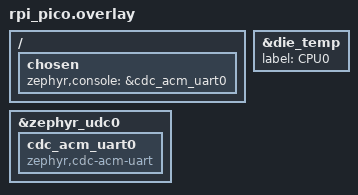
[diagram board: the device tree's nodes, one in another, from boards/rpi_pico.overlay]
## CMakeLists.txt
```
# SPDX-License-Identifier: Apache-2.0

cmake_minimum_required(VERSION 3.20.0)

find_package(Zephyr REQUIRED HINTS $ENV{ZEPHYR_BASE})
project(rpi_cpu_temp)

target_sources(app PRIVATE src/main.c)
```

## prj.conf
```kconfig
CONFIG_SENSOR=y
CONFIG_ADC=y
CONFIG_PRINTK=y
CONFIG_CBPRINTF_FP_SUPPORT=y

# Use UART over USB as a console
CONFIG_SERIAL=y
CONFIG_CONSOLE=y
CONFIG_UART_CONSOLE=y
CONFIG_UART_LINE_CTRL=y

# Use USB CDC ACM (whathever it means)
CONFIG_USB_DEVICE_STACK_NEXT=y
CONFIG_CDC_ACM_SERIAL_INITIALIZE_AT_BOOT=y
CONFIG_CDC_ACM_SERIAL_PID=0x0004
CONFIG_CDC_ACM_SERIAL_PRODUCT_STRING="Zephyr core temp"
```

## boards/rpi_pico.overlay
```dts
/*
 * SPDX-License-Identifier: Apache-2.0
 *
 * Copyright (c) 2023 TOKITA Hiroshi
 */

/ {
	chosen {
		zephyr,console = &cdc_acm_uart0;
	};
};

&die_temp {
	label = "CPU0";
	status = "okay";
};

&zephyr_udc0 {
	cdc_acm_uart0: cdc_acm_uart0 {
		compatible = "zephyr,cdc-acm-uart";
	};
};
```

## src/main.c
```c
/*
 * Copyright (c) 2023 TOKITA Hiroshi
 *
 * SPDX-License-Identifier: Apache-2.0
 */

#include <zephyr/device.h>
#include <zephyr/drivers/sensor.h>
#include <zephyr/kernel.h>
#include <zephyr/sys/printk.h>

/* RPI 2040 has a single sensor */
static const struct device *const sensor;

static int print_die_temperature(const struct device *dev) {
  struct sensor_value val;
  int rc;

  /* fetch sensor samples */
  rc = sensor_sample_fetch(dev);
  if (rc) {
    printk("Failed to fetch sample (%d)\n", rc);
    return rc;
  }

  rc = sensor_channel_get(dev, SENSOR_CHAN_DIE_TEMP, &val);
  if (rc) {
    printk("Failed to get data (%d)\n", rc);
    return rc;
  }

  printk("CPU Die temperature[%s]: %.1f °C\n", dev->name,
         sensor_value_to_double(&val));
  return 0;
}

int main(void) {
  k_msleep(500);
  int rc;

  if (!device_is_ready(sensor)) {
    printk("sensor: device %s not ready.\n", sensor->name);
    return 0;
  }

  while (1) {
    rc = print_die_temperature(sensor);
    if (rc < 0) {
      return 0;
    }
    k_msleep(1000);
  }
  return 0;
}
```
